AUTOSAR XML (schema 4-3-0)
package /ComponentTypes
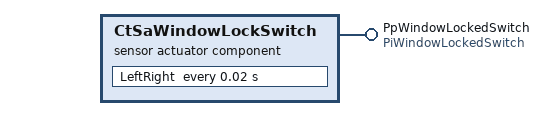
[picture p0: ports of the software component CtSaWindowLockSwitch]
  sensor actuator sw component type CtSaWindowLockSwitch
    provide port PpWindowLockedSwitch: nonqueued-sender-com-spec{data-element=DeWindowLock, init-value=0}, provided-interface=PiWindowLockedSwitch
    behavior CtSaWindowLockSwitch_InternalBehavior
      timing event TMT_LeftRight: start-on-event=LeftRight, period=0.02
      runnable LeftRight
        data-send-points:
          access SEND_PpWindowLockedSwitch_DeWindowLock: accessed-variable=PpWindowLockedSwitch.DeWindowLock
  swc implementation CtSaWindowLockSwitch_Implementation: behavior=CtSaWindowLockSwitch_InternalBehavior
